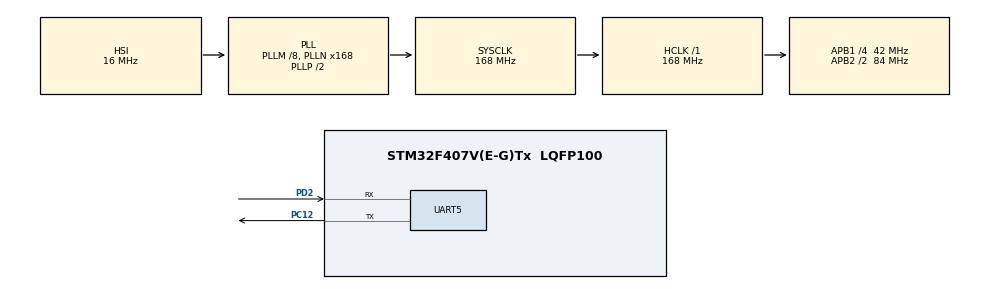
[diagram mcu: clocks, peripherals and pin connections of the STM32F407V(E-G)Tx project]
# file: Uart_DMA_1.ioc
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Dma.Request0=UART5_RX
Dma.UART5_RX.0.Direction=DMA_PERIPH_TO_MEMORY
Dma.UART5_RX.0.FIFOMode=DMA_FIFOMODE_DISABLE
Dma.UART5_RX.0.Instance=DMA1_Stream0
Dma.UART5_RX.0.MemDataAlignment=DMA_MDATAALIGN_BYTE
Dma.UART5_RX.0.MemInc=DMA_MINC_ENABLE
Dma.UART5_RX.0.Mode=DMA_NORMAL
Dma.UART5_RX.0.PeriphDataAlignment=DMA_PDATAALIGN_BYTE
Dma.UART5_RX.0.PeriphInc=DMA_PINC_DISABLE
Dma.UART5_RX.0.Priority=DMA_PRIORITY_LOW
Mcu.Family=STM32F4
Mcu.Name=STM32F407V(E-G)Tx
Mcu.Package=LQFP100
NVIC.DMA1_Stream0_IRQn=true\:0\:0\:false\:false\:true\:false\:true\:true
NVIC.PriorityGroup=NVIC_PRIORITYGROUP_4
NVIC.UART5_IRQn=true\:0\:0\:false\:false\:true\:true\:true\:true
PA13.Mode=Serial_Wire
PA13.Signal=SYS_JTMS-SWDIO
PA14.Mode=Serial_Wire
PA14.Signal=SYS_JTCK-SWCLK
PC12.Mode=Asynchronous
PC12.Signal=UART5_TX
PD2.Mode=Asynchronous
PD2.Signal=UART5_RX
PH0-OSC_IN.Mode=HSE-External-Oscillator
PH0-OSC_IN.Signal=RCC_OSC_IN
PH1-OSC_OUT.Mode=HSE-External-Oscillator
PH1-OSC_OUT.Signal=RCC_OSC_OUT
ProjectManager.HeapSize=0x200
ProjectManager.StackSize=0x400
ProjectManager.TargetToolchain=MDK-ARM V5
RCC.48MHZClocksFreq_Value=84000000
RCC.AHBFreq_Value=168000000
RCC.APB1CLKDivider=RCC_HCLK_DIV4
RCC.APB1Freq_Value=42000000
RCC.APB1TimFreq_Value=84000000
RCC.APB2CLKDivider=RCC_HCLK_DIV2
RCC.APB2Freq_Value=84000000
RCC.APB2TimFreq_Value=168000000
RCC.CortexFreq_Value=168000000
RCC.HCLKFreq_Value=168000000
RCC.HSE_VALUE=8000000
RCC.HSI_VALUE=16000000
RCC.LSE_VALUE=32768
RCC.PLLM=8
RCC.PLLN=168
RCC.SYSCLKFreq_VALUE=168000000
RCC.SYSCLKSource=RCC_SYSCLKSOURCE_PLLCLK
RCC.VCOOutputFreq_Value=336000000
UART5.VirtualMode=Asynchronous
board=custom

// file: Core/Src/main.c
/* USER CODE BEGIN Header */
/**
  ******************************************************************************
  * @file           : main.c
  * @brief          : Main program body
  ******************************************************************************
  * @attention
  *
  * Copyright (c) 2023 STMicroelectronics.
  * All rights reserved.
  *
  * This software is licensed under terms that can be found in the LICENSE file
  * in the root directory of this software component.
  * If no LICENSE file comes with this software, it is provided AS-IS.
  *
  ******************************************************************************
  */
/* USER CODE END Header */
#include "main.h"

/* USER CODE BEGIN Includes */
#include "string.h"
#include "math.h"
#include "stdlib.h"
/* USER CODE END Includes */

UART_HandleTypeDef huart5;
DMA_HandleTypeDef hdma_uart5_rx;

void SystemClock_Config(void);
static void MX_GPIO_Init(void);
static void MX_DMA_Init(void);
static void MX_UART5_Init(void);

/* USER CODE BEGIN 0 */

#define RxData_SIZE		9
#define MainBuf_SIZE	128

uint8_t RxData[RxData_SIZE];
uint8_t MainBuf[MainBuf_SIZE];
uint8_t TxData[]={0x5A, 0xA5, 0x05, 0x82, 0x50, 0x00, 0x00, 0x00};

volatile uint32_t count_DMA=0;

uint16_t oldPos = 0;
uint16_t newPos = 0;

int isOK = 0;

int change_to_page1=0;
int tedone=0, predone=0;

int TEMP , pressure;
uint8_t highByte, lowByte;

/* USER CODE END 0 */

int main(void)
{

  /* MCU Configuration--------------------------------------------------------*/

  /* Reset of all peripherals, Initializes the Flash interface and the Systick. */
  HAL_Init();

  /* Configure the system clock */
  SystemClock_Config();

  /* Initialize all configured peripherals */
  MX_GPIO_Init();
  MX_DMA_Init();
  MX_UART5_Init();
  /* USER CODE BEGIN 2 */

	TEMP = 926;
	pressure = 139;

	highByte = (uint8_t)((TEMP >>8) & 0xFF);
	lowByte = (uint8_t)((TEMP >>0) & 0xFF);

	TxData[6] = highByte;
	TxData[7] = lowByte;

	HAL_UART_Transmit(&huart5, TxData, sizeof(TxData),10);

	HAL_UARTEx_ReceiveToIdle_DMA(&huart5, MainBuf, MainBuf_SIZE);
	__HAL_DMA_DISABLE_IT(&hdma_uart5_rx, DMA_IT_HT);

//	HAL_UART_Receive_DMA(&huart5, MainBuf, MainBuf_SIZE);

  /* USER CODE END 2 */

  /* Infinite loop */
  while (1)
  {

    /* USER CODE BEGIN 3 */
		while(change_to_page1!=1)
		{
				if(TxData[4] == 0x50)
				{
					tedone=1;
					predone=0;
				}
				else if(TxData[4] == 0x51)
				{
					tedone=0;
					predone=1;
				}

				if(tedone==1 && predone==0)
				{
					TxData[4]=0x51;
					highByte = (uint8_t)((pressure >>8) & 0xFF);
					lowByte = (uint8_t)((pressure >>0) & 0xFF);

					TxData[6] = highByte;
					TxData[7] = lowByte;

					HAL_UART_Transmit(&huart5, TxData, sizeof(TxData),10);
				}
				else if(tedone==0 && predone==1)
				{
					TxData[4]=0x50;
					highByte = (uint8_t)((TEMP >>8) & 0xFF);
					lowByte = (uint8_t)((TEMP >>0) & 0xFF);

					TxData[6] = highByte;
					TxData[7] = lowByte;

					HAL_UART_Transmit(&huart5, TxData, sizeof(TxData),10);
				}
			}

  }
  /* USER CODE END 3 */
}

void SystemClock_Config(void)
{
  RCC_OscInitTypeDef RCC_OscInitStruct = {0};
  RCC_ClkInitTypeDef RCC_ClkInitStruct = {0};

  /** Configure the main internal regulator output voltage
  */
  __HAL_RCC_PWR_CLK_ENABLE();
  __HAL_PWR_VOLTAGESCALING_CONFIG(PWR_REGULATOR_VOLTAGE_SCALE1);

  /** Initializes the RCC Oscillators according to the specified parameters
  * in the RCC_OscInitTypeDef structure.
  */
  RCC_OscInitStruct.OscillatorType = RCC_OSCILLATORTYPE_HSI;
  RCC_OscInitStruct.HSIState = RCC_HSI_ON;
  RCC_OscInitStruct.HSICalibrationValue = RCC_HSICALIBRATION_DEFAULT;
  RCC_OscInitStruct.PLL.PLLState = RCC_PLL_ON;
  RCC_OscInitStruct.PLL.PLLSource = RCC_PLLSOURCE_HSI;
  RCC_OscInitStruct.PLL.PLLM = 8;
  RCC_OscInitStruct.PLL.PLLN = 168;
  RCC_OscInitStruct.PLL.PLLP = RCC_PLLP_DIV2;
  RCC_OscInitStruct.PLL.PLLQ = 4;
  if (HAL_RCC_OscConfig(&RCC_OscInitStruct) != HAL_OK)
  {
    Error_Handler();
  }

  /** Initializes the CPU, AHB and APB buses clocks
  */
  RCC_ClkInitStruct.ClockType = RCC_CLOCKTYPE_HCLK|RCC_CLOCKTYPE_SYSCLK
                              |RCC_CLOCKTYPE_PCLK1|RCC_CLOCKTYPE_PCLK2;
  RCC_ClkInitStruct.SYSCLKSource = RCC_SYSCLKSOURCE_PLLCLK;
  RCC_ClkInitStruct.AHBCLKDivider = RCC_SYSCLK_DIV1;
  RCC_ClkInitStruct.APB1CLKDivider = RCC_HCLK_DIV4;
  RCC_ClkInitStruct.APB2CLKDivider = RCC_HCLK_DIV2;

  if (HAL_RCC_ClockConfig(&RCC_ClkInitStruct, FLASH_LATENCY_5) != HAL_OK)
  {
    Error_Handler();
  }
}

static void MX_UART5_Init(void)
{

  huart5.Instance = UART5;
  huart5.Init.BaudRate = 115200;
  huart5.Init.WordLength = UART_WORDLENGTH_8B;
  huart5.Init.StopBits = UART_STOPBITS_1;
  huart5.Init.Parity = UART_PARITY_NONE;
  huart5.Init.Mode = UART_MODE_TX_RX;
  huart5.Init.HwFlowCtl = UART_HWCONTROL_NONE;
  huart5.Init.OverSampling = UART_OVERSAMPLING_16;
  if (HAL_UART_Init(&huart5) != HAL_OK)
  {
    Error_Handler();
  }

}

static void MX_DMA_Init(void)
{

  /* DMA controller clock enable */
  __HAL_RCC_DMA1_CLK_ENABLE();

  /* DMA interrupt init */
  /* DMA1_Stream0_IRQn interrupt configuration */
  HAL_NVIC_SetPriority(DMA1_Stream0_IRQn, 0, 0);
  HAL_NVIC_EnableIRQ(DMA1_Stream0_IRQn);

}

static void MX_GPIO_Init(void)
{

  /* GPIO Ports Clock Enable */
  __HAL_RCC_GPIOH_CLK_ENABLE();
  __HAL_RCC_GPIOA_CLK_ENABLE();
  __HAL_RCC_GPIOC_CLK_ENABLE();
  __HAL_RCC_GPIOD_CLK_ENABLE();

}

/* USER CODE BEGIN 4 */

//void HAL_UARTEx_RxEventCallback(UART_HandleTypeDef *huart, uint16_t Size)
//{
//	if(huart->Instance == UART5)
//	{
////		oldPos = newPos;  // Update the last position before copying new data

////		/* If the data in large and it is about to exceed the buffer size, we have to route it to the start of the buffer
////		 * This is to maintain the circular buffer
////		 * The old data in the main buffer will be overlapped
////		 */
////		if (oldPos+Size > MainBuf_SIZE)  // If the current position + new data size is greater than the main buffer
////		{
////			uint16_t datatocopy = MainBuf_SIZE-oldPos;  // find out how much space is left in the main buffer
////			memcpy ((uint8_t *)MainBuf+oldPos, RxData, datatocopy);  // copy data in that remaining space

////			oldPos = 0;  // point to the start of the buffer
////			memcpy ((uint8_t *)MainBuf, (uint8_t *)RxData+datatocopy, (Size-datatocopy));  // copy the remaining data
////			newPos = (Size-datatocopy);  // update the position
////		}

////		/* if the current position + new data size is less than the main buffer
////		 * we will simply copy the data into the buffer and update the position
////		 */
////		else
////		{
////			memcpy ((uint8_t *)MainBuf+oldPos, RxData, Size);
////			newPos = Size+oldPos;
////		}
//
//		for(int i = 0; i<MainBuf_SIZE; i++)
//		{
//			if(MainBuf[i]==0x5A && MainBuf[i+3]==0x83 && MainBuf[i+4]==0x11 && MainBuf[i+5]==0x01)
//			{
//				change_to_page1=1;
//			}
//			else if(MainBuf[i]==0x5A && MainBuf[i+3]==0x83 && MainBuf[i+4]==0x11 && MainBuf[i+5]==0x02)
//				change_to_page1=0;
//		}
//
//		/* Start DMA again */
////		HAL_UARTEx_ReceiveToIdle_DMA(&huart5, RxData, RxData_SIZE);
////		__HAL_DMA_DISABLE_IT(&hdma_uart5_rx, DMA_IT_HT);
//	}
//}

void HAL_UARTEx_RxEventCallback(UART_HandleTypeDef *huart, uint16_t Size)
{
//	if(huart->Instance == UART5)
//	{
		count_DMA++;
		for(int i = 0; i<MainBuf_SIZE; i++)
		{
			if(i<=120)
			{
				if(MainBuf[i]==0x5A && MainBuf[i+3]==0x83 && MainBuf[i+4]==0x11 && MainBuf[i+5]==0x01)
					change_to_page1=1;
			}
//			else /*if(MainBuf[i]==0x5A && MainBuf[i+3]==0x83 && MainBuf[i+4]==0x11 && MainBuf[i+5]==0x02)*/
//					change_to_page1=0;
		}
//	}

		/* Start DMA again */
		HAL_UARTEx_ReceiveToIdle_DMA(&huart5, MainBuf, MainBuf_SIZE);
		__HAL_DMA_DISABLE_IT(&hdma_uart5_rx, DMA_IT_HT);
}

//void HAL_UART_TxCpltCallback(UART_HandleTypeDef *huart)
//{
//	while(change_to_page1!=1)
//		{
//			int i=0;
//			i++;
//			//HAL_UART_Transmit(&huart5, TxData, sizeof(TxData),10);
//			if(i==1000)
//			{
//				if(TxData[4] == 0x50)
//				{
//					tedone=1;
//					predone=0;
//				}
//				else if(TxData[4] == 0x51)
//				{
//					tedone=0;
//					predone=1;
//				}
//
//				if(tedone==1 && predone==0)
//				{
//					TxData[4]=0x51;
//					highByte = (uint8_t)((pressure >>8) & 0xFF);
//					lowByte = (uint8_t)((pressure >>0) & 0xFF);
//
//					TxData[6] = highByte;
//					TxData[7] = lowByte;
//
//					HAL_UART_Transmit_IT(&huart5, TxData, sizeof(TxData));
//				}
//				else if(tedone==0 && predone==1)
//				{
//					TxData[4]=0x50;
//					highByte = (uint8_t)((TEMP >>8) & 0xFF);
//					lowByte = (uint8_t)((TEMP >>0) & 0xFF);
//
//					TxData[6] = highByte;
//					TxData[7] = lowByte;
//
//					HAL_UART_Transmit_IT(&huart5, TxData, sizeof(TxData));
//				}
//				i=0;
//			}
//		}
//}
/* USER CODE END 4 */

void Error_Handler(void)
{
  __disable_irq();
  while (1)
  {
  }
}
